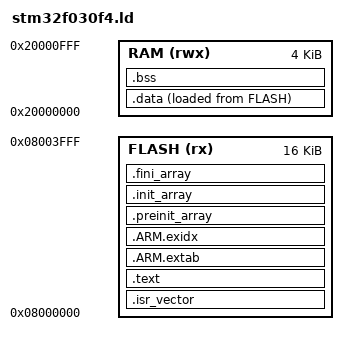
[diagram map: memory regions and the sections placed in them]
ENTRY(Reset_Handler)

MEMORY
{
    FLASH (rx)  : ORIGIN = 0x08000000, LENGTH = 16K
    RAM   (rwx) : ORIGIN = 0x20000000, LENGTH = 4K
}

_estack = ORIGIN(RAM) + LENGTH(RAM);
_Min_Stack_Size = 0x200;
_stack_limit = _estack - _Min_Stack_Size;

SECTIONS
{
    .isr_vector ORIGIN(FLASH) :
    {
        . = ALIGN(4);
        KEEP(*(.isr_vector))
        . = ALIGN(4);
    } > FLASH

    .text :
    {
        . = ALIGN(4);
        *(.text*)
        *(.rodata*)
        KEEP(*(.init))
        KEEP(*(.fini))
        . = ALIGN(4);
        _etext = .;
    } > FLASH

    .ARM.extab :
    {
        *(.ARM.extab* .gnu.linkonce.armextab.*)
    } > FLASH

    .ARM.exidx :
    {
        __exidx_start = .;
        *(.ARM.exidx*)
        __exidx_end = .;
    } > FLASH

    .preinit_array :
    {
        PROVIDE_HIDDEN(__preinit_array_start = .);
        KEEP(*(.preinit_array*))
        PROVIDE_HIDDEN(__preinit_array_end = .);
    } > FLASH

    .init_array :
    {
        PROVIDE_HIDDEN(__init_array_start = .);
        KEEP(*(SORT(.init_array.*)))
        KEEP(*(.init_array*))
        PROVIDE_HIDDEN(__init_array_end = .);
    } > FLASH

    .fini_array :
    {
        PROVIDE_HIDDEN(__fini_array_start = .);
        KEEP(*(SORT(.fini_array.*)))
        KEEP(*(.fini_array*))
        PROVIDE_HIDDEN(__fini_array_end = .);
    } > FLASH

    _sidata = LOADADDR(.data);
    .data :
    {
        . = ALIGN(4);
        _sdata = .;
        *(.data*)
        . = ALIGN(4);
        _edata = .;
    } > RAM AT > FLASH

    .bss (NOLOAD) :
    {
        . = ALIGN(4);
        _sbss = .;
        *(.bss*)
        *(COMMON)
        . = ALIGN(4);
        _ebss = .;
    } > RAM

    /DISCARD/ :
    {
        *(.note*)
        *(.comment*)
    }
}

ASSERT(_ebss <= _stack_limit, "RAM overflow: data and bss overlap stack")
